# dma register map
Vendor: Texas Instruments
Peripheral module from a debugger description file (folder MSP432).
Registers are 32-bit, read-write, no defined reset value unless marked. A register's access mark holds for its fields unless they carry their own. Offsets are as the file gives them; lines under a group give offsets from that group; [hi:lo] are bit positions; {n}, {i} and the like mark numbered series; 'fields as' and 'values as' point back to an identical list; <NAME> marks a mode.

## DMA
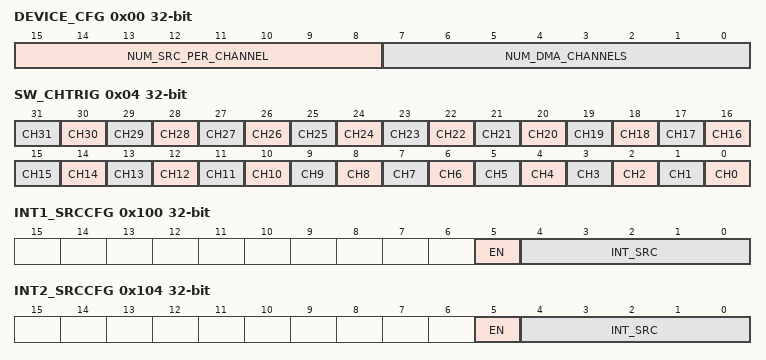
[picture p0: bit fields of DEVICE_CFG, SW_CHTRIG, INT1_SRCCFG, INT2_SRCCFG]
0x00 DEVICE_CFG — Device Configuration Status
  [15:8] NUM_SRC_PER_CHANNEL — Reflects the number of DMA sources per channel
  [7:0] NUM_DMA_CHANNELS — Reflects the number of DMA channels available on the device
0x00 INTEGRATION_CFG access not given — Integration Configuration Register
0x04 SW_CHTRIG — Software Channel Trigger Register
  [n] CH{n} (n=0..31) — Write 1 triggers DMA_CHANNEL{n}
0x08 STALL_STATUS access not given
{0x10+4i} CH_SRCCFG{i} (i=0..31) — Channel n Source Configuration Register
  [7:0] DMA_SRC — Controls which device level DMA source is mapped to the channel
0x10 REQ_STATUS access not given — Request Status Register
0x18 SREQ_STATUS access not given — Single Request Status Register
0x20 DONE_SET access not given
0x24 DONE_CLR access not given — Done Clear Register
0x28 ACTIVE_SET access not given
0x2C ACTIVE_CLR access not given — Active Clear Register
0x48 ERR_SET access not given — Bus Error Set Register
0x100 INT1_SRCCFG — Interrupt 1 Source Channel Configuration
  [5] EN — When 1, enables the DMA_INT1 mapping.
  [4:0] INT_SRC — Controls which channel's completion event is mapped as a source
0x104 INT2_SRCCFG — Interrupt 2 Source Channel Configuration Register
  [5] EN — When 1, enables the DMA_INT2 mapping.
  [4:0] INT_SRC — Controls which channel's completion event is mapped as a source
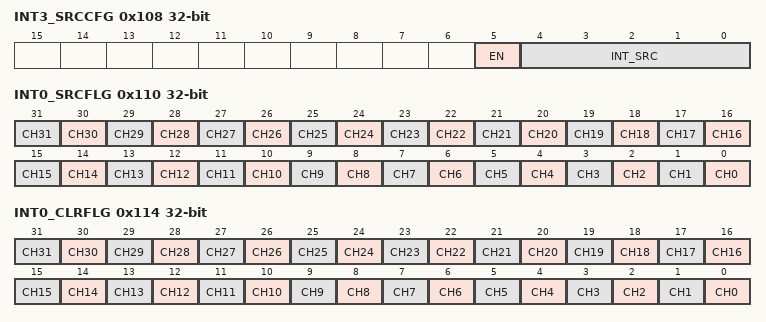
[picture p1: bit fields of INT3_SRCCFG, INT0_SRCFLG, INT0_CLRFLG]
0x108 INT3_SRCCFG — Interrupt 3 Source Channel Configuration Register
  [5] EN — When 1, enables the DMA_INT3 mapping.
  [4:0] INT_SRC — Controls which channel's completion event is mapped as a source
0x110 INT0_SRCFLG — Interrupt 0 Source Channel Flag Register
  [n] CH{n} (n=0..31) — If 1, indicates that Channel {n} was the source of DMA_INT0
0x114 INT0_CLRFLG — Interrupt 0 Source Channel Clear Flag Register
  [n] CH{n} (n=0..31) — Write 1 clears the corresponding flag bit in the DMA_INT0_SRCFL
